AUTOSAR XML (schema 4-2-2)
standard types defined: float32, uint16, sint16, float32_DataConstr, uint16_DataConstr, sint16_DataConstr
package /Company/Components
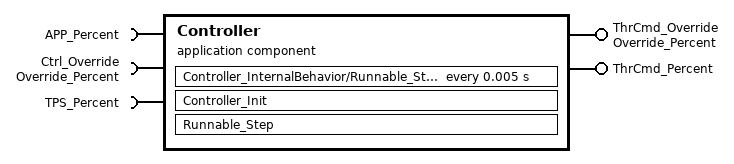
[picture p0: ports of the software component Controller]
  application sw component type Controller
    provide port ThrCmd_Override: nonqueued-sender-com-spec{data-element=Override_Percent/Value, init-value=0}, provided-interface=Override_Percent
    provide port ThrCmd_Percent: nonqueued-sender-com-spec{data-element=ThrCmd_Percent/Value, init-value=0}, provided-interface=ThrCmd_Percent
    require port APP_Percent: nonqueued-receiver-com-spec{data-element=APP_Percent/Value, filter=data-filter-type=ALWAYS, init-value=0}, required-interface=APP_Percent
    require port Ctrl_Override: nonqueued-receiver-com-spec{data-element=Override_Percent/Value, filter=data-filter-type=ALWAYS, init-value=0}, required-interface=Override_Percent
    require port TPS_Percent: nonqueued-receiver-com-spec{data-element=TPS_Percent/Value, filter=data-filter-type=ALWAYS, init-value=0}, required-interface=TPS_Percent
    behavior Controller_InternalBehavior
      init event Controller_InitEvent: start-on-event=Controller_Init
      timing event Event_Runnable_Step: start-on-event=Controller_InternalBehavior/Runnable_Step, period=0.005
      runnable Controller_Init
      runnable Runnable_Step
        data-read-access:
          access READ_APP_Percent_Value: accessed-variable=APP_Percent.Value
          access READ_TPS_Percent_Value: accessed-variable=TPS_Percent.Value
        data-receive-point-by-arguments:
          access REC_Ctrl_Override_Value: accessed-variable=Ctrl_Override.Value
        data-send-points:
          access SEND_ThrCmd_Override_Value: accessed-variable=ThrCmd_Override.Value
        data-write-access:
          access WRITE_ThrCmd_Percent_Value: accessed-variable=ThrCmd_Percent.Value
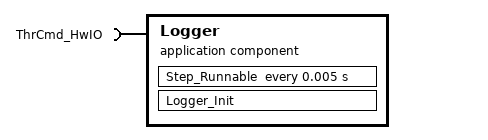
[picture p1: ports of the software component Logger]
  application sw component type Logger
    require port ThrCmd_HwIO: nonqueued-receiver-com-spec{data-element=ThrCmd_HwIO/Value, filter=data-filter-type=ALWAYS, init-value=0}, required-interface=ThrCmd_HwIO
    behavior Logger_InternalBehavior
      init event Logger_InitEvent: start-on-event=Logger_Init
      timing event Event_Step_Runnable: start-on-event=Step_Runnable, period=0.005
      runnable Logger_Init
      runnable Step_Runnable
        data-receive-point-by-arguments:
          access REC_ThrCmd_HwIO_Value: accessed-variable=ThrCmd_HwIO.Value
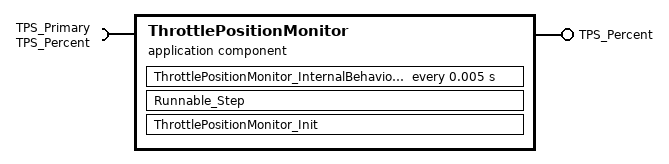
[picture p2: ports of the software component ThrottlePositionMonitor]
  application sw component type ThrottlePositionMonitor
    provide port TPS_Percent: nonqueued-sender-com-spec{data-element=TPS_Percent/Value, init-value=0}, provided-interface=TPS_Percent
    require port TPS_Primary: nonqueued-receiver-com-spec{data-element=TPS_Percent/Value, filter=data-filter-type=ALWAYS, init-value=0}, required-interface=TPS_Percent
    behavior ThrottlePositionMonitor_InternalBehavior
      timing event Event_Runnable_Step: start-on-event=ThrottlePositionMonitor_InternalBehavior/Runnable_Step, period=0.005
      init event ThrottlePositionMonitor_InitEvent: start-on-event=ThrottlePositionMonitor_Init
      runnable Runnable_Step
        data-read-access:
          access READ_TPS_Primary_Value: accessed-variable=TPS_Primary.Value
        data-write-access:
          access WRITE_TPS_Percent_Value: accessed-variable=TPS_Percent.Value
      runnable ThrottlePositionMonitor_Init
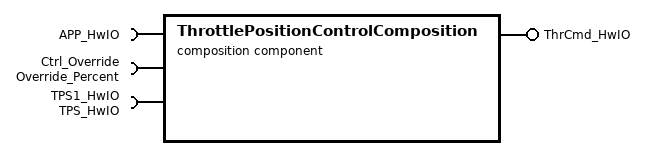
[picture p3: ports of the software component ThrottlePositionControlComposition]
  composition sw component type ThrottlePositionControlComposition
    provide port ThrCmd_HwIO: nonqueued-sender-com-spec{data-element=ThrCmd_HwIO/Value, init-value=0}, provided-interface=ThrCmd_HwIO
    require port APP_HwIO: nonqueued-receiver-com-spec{data-element=APP_HwIO/Value, filter=data-filter-type=ALWAYS}, required-interface=APP_HwIO
    require port Ctrl_Override: nonqueued-receiver-com-spec{data-element=Override_Percent/Value, filter=data-filter-type=ALWAYS}, required-interface=Override_Percent
    require port TPS1_HwIO: nonqueued-receiver-com-spec{data-element=TPS_HwIO/Value, filter=data-filter-type=ALWAYS, init-value=0}, required-interface=TPS_HwIO
    6 x component:
      Actuator: type=ThrottlePositionActuator
      APPSnsr: type=AccelerationPedalPositionSensor
      Controller: type=Controller
      Logger: type=Logger
      Monitor: type=ThrottlePositionMonitor
      TPS_Primary: type=ThrottlePositionSensor
    connect Actuator.ThrCmd_HwIO -> Logger.ThrCmd_HwIO
    connect APPSnsr.APP_Percent -> Controller.APP_Percent
    connect Controller.ThrCmd_Override -> Actuator.ThrCmd_Override
    connect Controller.ThrCmd_Percent -> Actuator.ThrCmd_Percent
    connect Monitor.TPS_Percent -> Controller.TPS_Percent
    connect TPS_Primary.TPS_Percent -> Monitor.TPS_Primary
    delegate APPSnsr.APP_HwIO <-> outer port ThrottlePositionControlComposition/APP_HwIO
    delegate Controller.Ctrl_Override <-> outer port ThrottlePositionControlComposition/Ctrl_Override
    delegate Actuator.ThrCmd_HwIO <-> outer port ThrottlePositionControlComposition/ThrCmd_HwIO
    delegate TPS_Primary.TPS_HwIO <-> outer port TPS1_HwIO
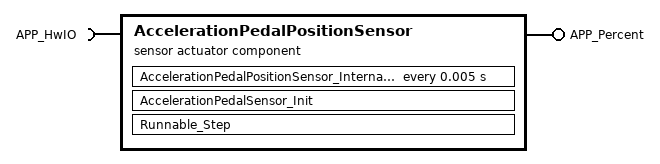
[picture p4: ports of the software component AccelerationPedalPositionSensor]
  sensor actuator sw component type AccelerationPedalPositionSensor
    provide port APP_Percent: nonqueued-sender-com-spec{data-element=APP_Percent/Value, init-value=0}, provided-interface=APP_Percent
    require port APP_HwIO: nonqueued-receiver-com-spec{data-element=APP_HwIO/Value, filter=data-filter-type=ALWAYS, init-value=0}, required-interface=APP_HwIO
    behavior AccelerationPedalPositionSensor_InternalBehavior
      init event AccelerationPedalSensor_InitEvent: start-on-event=AccelerationPedalSensor_Init
      timing event Event_Runnable_Step: start-on-event=AccelerationPedalPositionSensor_InternalBehavior/Runnable_Step, period=0.005
      runnable AccelerationPedalSensor_Init
      runnable Runnable_Step
        data-read-access:
          access READ_APP_HwIO_Value: accessed-variable=APP_HwIO.Value
        data-write-access:
          access WRITE_APP_Percent_Value: accessed-variable=APP_Percent.Value
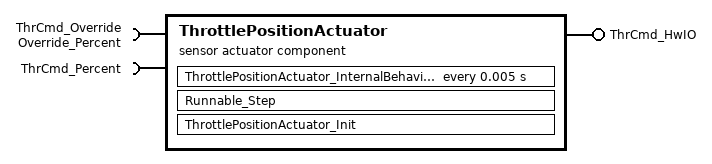
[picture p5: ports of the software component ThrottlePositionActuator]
  sensor actuator sw component type ThrottlePositionActuator
    provide port ThrCmd_HwIO: nonqueued-sender-com-spec{data-element=ThrCmd_HwIO/Value, init-value=0}, provided-interface=ThrCmd_HwIO
    require port ThrCmd_Override: nonqueued-receiver-com-spec{data-element=Override_Percent/Value, filter=data-filter-type=ALWAYS, init-value=0}, required-interface=Override_Percent
    require port ThrCmd_Percent: nonqueued-receiver-com-spec{data-element=ThrCmd_Percent/Value, filter=data-filter-type=ALWAYS, init-value=0}, required-interface=ThrCmd_Percent
    behavior ThrottlePositionActuator_InternalBehavior
      timing event Event_Runnable_Step: start-on-event=ThrottlePositionActuator_InternalBehavior/Runnable_Step, period=0.005
      init event ThrottlePositionActuator_InitEvent: start-on-event=ThrottlePositionActuator_Init
      runnable Runnable_Step
        data-receive-point-by-arguments:
          access REC_ThrCmd_Override_Value: accessed-variable=ThrCmd_Override.Value
          access REC_ThrCmd_Percent_Value: accessed-variable=ThrCmd_Percent.Value
        data-write-access:
          access WRITE_ThrCmd_HwIO_Value: accessed-variable=ThrCmd_HwIO.Value
      runnable ThrottlePositionActuator_Init
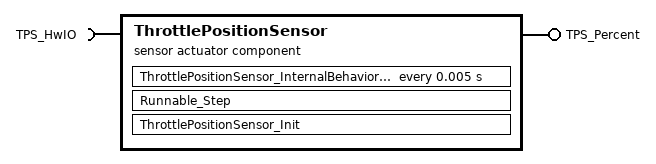
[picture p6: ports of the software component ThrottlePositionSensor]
  sensor actuator sw component type ThrottlePositionSensor
    provide port TPS_Percent: nonqueued-sender-com-spec{data-element=TPS_Percent/Value, init-value=0}, provided-interface=TPS_Percent
    require port TPS_HwIO: nonqueued-receiver-com-spec{data-element=TPS_HwIO/Value, filter=data-filter-type=ALWAYS, init-value=0}, required-interface=TPS_HwIO
    behavior ThrottlePositionSensor_InternalBehavior: supports-multiple-instantiation=true
      timing event Event_Runnable_Step: start-on-event=ThrottlePositionSensor_InternalBehavior/Runnable_Step, period=0.005
      init event ThrottlePositionSensor_InitEvent: start-on-event=ThrottlePositionSensor_Init
      runnable Runnable_Step
        data-read-access:
          access REC_TPS_HwIO_Value: accessed-variable=TPS_HwIO.Value
        data-write-access:
          access SEND_TPS_Percent_Value: accessed-variable=TPS_Percent.Value
      runnable ThrottlePositionSensor_Init
  6 x swc implementation:
    AccelerationPedalPositionSensor_Implementation: behavior=AccelerationPedalPositionSensor_InternalBehavior
      code-descriptors:
        code Default: artifact-descriptors=autosar-engineering-object={short-label=Default, category=SWSRC}
    Controller_Implementation: behavior=Controller_InternalBehavior
      code-descriptors:
        code Default: artifact-descriptors=autosar-engineering-object={short-label=Default, category=SWSRC}
    Logger_Implementation: behavior=Logger_InternalBehavior
      code-descriptors:
        code Default: artifact-descriptors=autosar-engineering-object={short-label=Default, category=SWSRC}
    ThrottlePositionActuator_Implementation: behavior=ThrottlePositionActuator_InternalBehavior
      code-descriptors:
        code Default: artifact-descriptors=autosar-engineering-object={short-label=Default, category=SWSRC}
    ThrottlePositionMonitor_Implementation: behavior=ThrottlePositionMonitor_InternalBehavior
      code-descriptors:
        code Default: artifact-descriptors=autosar-engineering-object={short-label=Default, category=SWSRC}
    ThrottlePositionSensor_Implementation: behavior=ThrottlePositionSensor_InternalBehavior
      code-descriptors:
        code Default: artifact-descriptors=autosar-engineering-object={short-label=Default, category=SWSRC}
package /Company/Interfaces
  7 x sender receiver interface:
    APP_HwIO: invalidation-policy{data-element=APP_HwIO/Value, handle-invalid=DONT-INVALIDATE}
      data Value: type=uint16
    APP_Percent: invalidation-policy{data-element=APP_Percent/Value, handle-invalid=DONT-INVALIDATE}
      data Value: type=float32
    Override_Percent: invalidation-policy{data-element=Override_Percent/Value, handle-invalid=DONT-INVALIDATE}
      data Value: type=float32
    ThrCmd_HwIO: invalidation-policy{data-element=ThrCmd_HwIO/Value, handle-invalid=DONT-INVALIDATE}
      data Value: type=sint16
    ThrCmd_Percent: invalidation-policy{data-element=ThrCmd_Percent/Value, handle-invalid=DONT-INVALIDATE}
      data Value: type=float32
    TPS_HwIO: invalidation-policy{data-element=TPS_HwIO/Value, handle-invalid=DONT-INVALIDATE}
      data Value: type=uint16
    TPS_Percent: invalidation-policy{data-element=TPS_Percent/Value, handle-invalid=DONT-INVALIDATE}
      data Value: type=float32
